# STM32L4R7 register map
File version: 2.0
CPU: CM4 r0p1, little endian, MPU, FPU, 4 interrupt priority bits
Registers are 32-bit, read-write, reset 0x0 unless marked. A register's access mark holds for its fields unless they carry their own. Offsets are from the block's base; [hi:lo] are bit positions; {n}, {i} and the like mark numbered series; 'fields as' and 'values as' point back to an identical list; <NAME> marks a mode.

## TIM2 — General-purpose-timers
Base 0x40000000
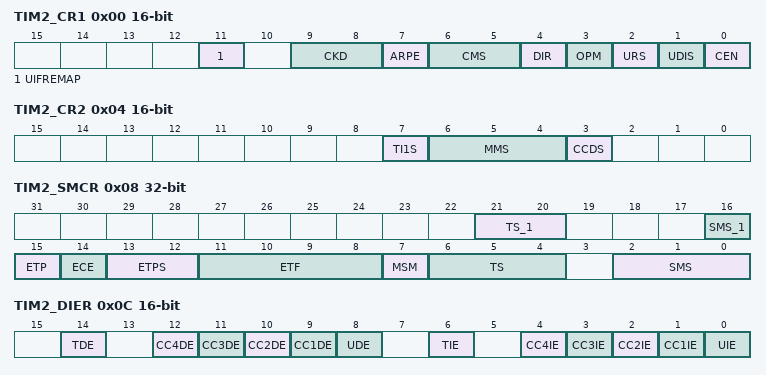
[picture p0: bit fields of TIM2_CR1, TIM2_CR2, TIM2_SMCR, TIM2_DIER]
0x00 TIM2_CR1 16-bit — TIM2 control register 1
  [11] UIFREMAP — UIF status bit remapping
    0=No remapping. UIF status bit is not copied to TIMx_CNT register bit 31.; 1=Remapping enabled. UIF status bit is copied to TIMx_CNT register bit 31.
  [9:8] CKD — Clock division This bit-field indicates the division ratio between the timer clock (CK_INT) frequency and sampling clock used by the digital filters (ETR, TIx),
    0=t<sub>DTS</sub> = t<sub>CK_INT</sub>; 1=t<sub>DTS</sub> = 2 t<sub>CK_INT</sub>; 2=t<sub>DTS</sub> = 4 t<sub>CK_INT</sub>
  [7] ARPE — Auto-reload preload enable
    0=TIMx_ARR register is not buffered; 1=TIMx_ARR register is buffered
  [6:5] CMS — Center-aligned mode selection Note: It is not allowed to switch from edge-aligned mode to center-aligned mode as long as the counter is enabled (CEN=1)
    0=Edge-aligned mode. The counter counts up or down depending on the direction bit (DIR).; 1=Center-aligned mode 1. The counter counts up and down alternatively. Output compare interrupt flags of channels configured in output (CCxS=00 in TIMx_CCMRx register) are set only when the counter is counting down.; 2=Center-aligned mode 2. The counter counts up and down alternatively. Output compare interrupt flags of channels configured in output (CCxS=00 in TIMx_CCMRx register) are set only when the counter is counting up.; 3=Center-aligned mode 3. The counter counts up and down alternatively. Output compare interrupt flags of channels configured in output (CCxS=00 in TIMx_CCMRx register) are set both when the counter is counting up or down.
  [4] DIR — Direction Note: This bit is read only when the timer is configured in Center-aligned mode or Encoder mode.
    0=Counter used as upcounter; 1=Counter used as downcounter
  [3] OPM — One-pulse mode
    0=Counter is not stopped at update event; 1=Counter stops counting at the next update event (clearing the bit CEN)
  [2] URS — Update request source This bit is set and cleared by software to select the UEV event sources. Counter overflow/underflow Setting the UG bit Update generation through the slave mode controller
    0=Any of the following events generate an update interrupt or DMA request if enabled. These events can be:; 1=Only counter overflow/underflow generates an update interrupt or DMA request if enabled
  [1] UDIS — Update disable This bit is set and cleared by software to enable/disable UEV event generation. Counter overflow/underflow Setting the UG bit Update generation through the slave mode controller Buffered registers are then loaded with their preload values.
    0=UEV enabled. The Update (UEV) event is generated by one of the following events:; 1=UEV disabled. The Update event is not generated, shadow registers keep their value (ARR, PSC, CCRx). However the counter and the prescaler are reinitialized if the UG bit is set or if a hardware reset is received from the slave mode controller.
  [0] CEN — Counter enable Note: External clock, gated mode and encoder mode can work only if the CEN bit has been previously set by software. However trigger mode can set the CEN bit automatically by hardware. CEN is cleared automatically in one-pulse mode, when an update event occurs.
    0=Counter disabled; 1=Counter enabled
0x04 TIM2_CR2 16-bit — TIM2 control register 2
  [7] TI1S — TI1 selection
    0=The TIMx_CH1 pin is connected to TI1 input; 1=The TIMx_CH1, CH2 and CH3 pins are connected to the TI1 input (XOR combination) See also Section 24.3.25: Interfacing with Hall sensors on page 713
  [6:4] MMS — Master mode selection These bits permit to select the information to be sent in master mode to slave timers for synchronization (TRGO). The combination is as follows: When the Counter Enable signal is controlled by the trigger input, there is a delay on TRGO, except if the master/slave mode is selected (see the MSM bit description in TIMx_SMCR register). Note: The clock of the slave timer or ADC must be enabled prior to receive events from the master timer, and must not be changed on-the-fly while triggers are received from the master timer.
    0=Reset - the UG bit from the TIMx_EGR register is used as trigger output (TRGO). If the reset is generated by the trigger input (slave mode controller configured in reset mode) then the signal on TRGO is delayed compared to the actual reset.; 1=Enable - the Counter enable signal, CNT_EN, is used as trigger output (TRGO). It is useful to start several timers at the same time or to control a window in which a slave timer is enabled. The Counter Enable signal is generated by a logic AND between CEN control bit and the trigger input when configured in gated mode.; 2=Update - The update event is selected as trigger output (TRGO). For instance a master timer can then be used as a prescaler for a slave timer.; 3=Compare Pulse - The trigger output send a positive pulse when the CC1IF flag is to be set (even if it was already high), as soon as a capture or a compare match occurred. (TRGO); {v}=Compare - OC{v-3}REFC signal is used as trigger output (TRGO) (v=4..7)
  [3] CCDS — Capture/compare DMA selection
    0=CCx DMA request sent when CCx event occurs; 1=CCx DMA requests sent when update event occurs
0x08 TIM2_SMCR — TIM2 slave mode control register
  [21:20] TS_1 — TS[4:3]
  [16] SMS_1 — SMS[3]
  [15] ETP — External trigger polarity This bit selects whether ETR or ETR is used for trigger operations
    0=ETR is non-inverted, active at high level or rising edge; 1=ETR is inverted, active at low level or falling edge
  [14] ECE — External clock enable This bit enables External clock mode 2. Note: Setting the ECE bit has the same effect as selecting external clock mode 1 with TRGI connected to ETRF (SMS=111 and TS=00111). Note: It is possible to simultaneously use external clock mode 2 with the following slave modes: reset mode, gated mode and trigger mode. Nevertheless, TRGI must not be connected to ETRF in this case (TS bits must not be 00111). Note: If external clock mode 1 and external clock mode 2 are enabled at the same time, the external clock input is ETRF.
    0=External clock mode 2 disabled; 1=External clock mode 2 enabled. The counter is clocked by any active edge on the ETRF signal.
  [13:12] ETPS — External trigger prescaler External trigger signal ETRP frequency must be at most 1/4 of CK_INT frequency. A prescaler can be enabled to reduce ETRP frequency. It is useful when inputting fast external clocks.
    0=Prescaler OFF; 1=ETRP frequency divided by 2; 2=ETRP frequency divided by 4; 3=ETRP frequency divided by 8
  [11:8] ETF — External trigger filter This bit-field then defines the frequency used to sample ETRP signal and the length of the digital filter applied to ETRP. The digital filter is made of an event counter in which N consecutive events are needed to validate a transition on the output:
    0=No filter, sampling is done at f<sub>DTS</sub>; 1=f<sub>SAMPLING</sub>=f<sub>CK_INT</sub>, N=2; 2=f<sub>SAMPLING</sub>=f<sub>CK_INT</sub>, N=4; 3=f<sub>SAMPLING</sub>=f<sub>CK_INT</sub>, N=8; 4=f<sub>SAMPLING</sub>=f<sub>DTS</sub>/2, N=6; 5=f<sub>SAMPLING</sub>=f<sub>DTS</sub>/2, N=8; 6=f<sub>SAMPLING</sub>=f<sub>DTS</sub>/4, N=6; 7=f<sub>SAMPLING</sub>=f<sub>DTS</sub>/4, N=8; 8=f<sub>SAMPLING</sub>=f<sub>DTS</sub>/8, N=6; 9=f<sub>SAMPLING</sub>=f<sub>DTS</sub>/8, N=8; 10=f<sub>SAMPLING</sub>=f<sub>DTS</sub>/16, N=5; 11=f<sub>SAMPLING</sub>=f<sub>DTS</sub>/16, N=6; 12=f<sub>SAMPLING</sub>=f<sub>DTS</sub>/16, N=8; 13=f<sub>SAMPLING</sub>=f<sub>DTS</sub>/32, N=5; 14=f<sub>SAMPLING</sub>=f<sub>DTS</sub>/32, N=6; 15=f<sub>SAMPLING</sub>=f<sub>DTS</sub>/32, N=8
  [7] MSM — Master/Slave mode
    0=No action; 1=The effect of an event on the trigger input (TRGI) is delayed to allow a perfect synchronization between the current timer and its slaves (through TRGO). It is useful if we want to synchronize several timers on a single external event.
  [6:4] TS — TS[0]: Trigger selection This bit-field selects the trigger input to be used to synchronize the counter. Others: Reserved See Table 179: TIMx internal trigger connection on page 846 for more details on ITRx meaning for each Timer. Note: These bits must be changed only when they are not used (e.g. when SMS=000) to avoid wrong edge detections at the transition.
    {v}=Internal Trigger {v} (ITR{v}) (v=0..3); 4=TI1 Edge Detector (TI1F_ED); 5=Filtered Timer Input 1 (TI1FP1); 6=Filtered Timer Input 2 (TI2FP2); 7=External Trigger input (ETRF)
  [2:0] SMS — SMS[0]: Slave mode selection When external signals are selected the active edge of the trigger signal (TRGI) is linked to the polarity selected on the external input (see Input Control register and Control Register description. reinitializes the counter, generates an update of the registers and starts the counter. Note: The gated mode must not be used if TI1F_ED is selected as the trigger input (TS=00100). Indeed, TI1F_ED outputs 1 pulse for each transition on TI1F, whereas the gated mode checks the level of the trigger signal. Note: The clock of the slave peripherals (timer, ADC, ...) receiving the TRGO or the TRGO2 signals must be enabled prior to receive events from the master timer, and the clock frequency (prescaler) must not be changed on-the-fly while triggers are received from the master timer.
    0=Slave mode disabled - if CEN = 1 then the prescaler is clocked directly by the internal clock; 1=Encoder mode 1 - Counter counts up/down on TI1FP1 edge depending on TI2FP2 level; 2=Encoder mode 2 - Counter counts up/down on TI2FP2 edge depending on TI1FP1 level; 3=Encoder mode 3 - Counter counts up/down on both TI1FP1 and TI2FP2 edges depending on the level of the other input; 4=Reset Mode - Rising edge of the selected trigger input (TRGI) reinitializes the counter and generates an update of the registers; 5=Gated Mode - The counter clock is enabled when the trigger input (TRGI) is high. The counter stops (but is not reset) as soon as the trigger becomes low. Both start and stop of the counter are controlled.; 6=Trigger Mode - The counter starts at a rising edge of the trigger TRGI (but it is not reset). Only the start of the counter is controlled.; 7=External Clock Mode 1 - Rising edges of the selected trigger (TRGI) clock the counter
0x0C TIM2_DIER 16-bit — TIM2 DMA/Interrupt enable register
  [14] TDE — Trigger DMA request enable
    0=Trigger DMA request disabled; 1=Trigger DMA request enabled
  [n+8] CC{n}DE (n=1..4) — Capture/Compare {n} DMA request enable
    0=CC{n} DMA request disabled; 1=CC{n} DMA request enabled
  [8] UDE — Update DMA request enable
    0=Update DMA request disabled; 1=Update DMA request enabled
  [6] TIE — Trigger interrupt enable
    0=Trigger interrupt disabled; 1=Trigger interrupt enabled
  [n] CC{n}IE (n=1..4) — Capture/Compare {n} interrupt enable
    0=CC{n} interrupt disabled; 1=CC{n} interrupt enabled
  [0] UIE — Update interrupt enable
    0=Update interrupt disabled; 1=Update interrupt enabled
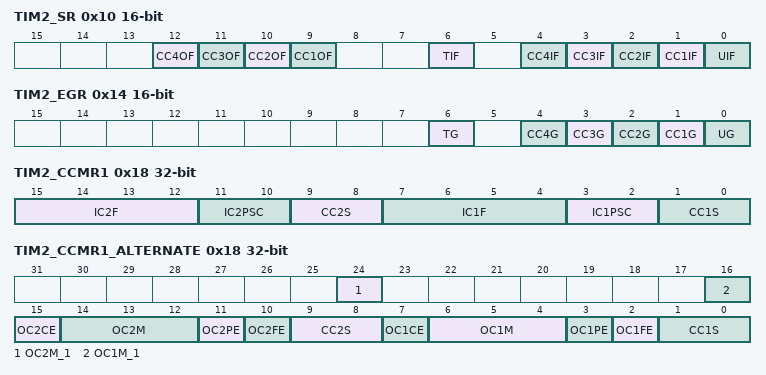
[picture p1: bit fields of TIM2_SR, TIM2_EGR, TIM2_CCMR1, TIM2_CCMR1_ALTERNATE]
0x10 TIM2_SR 16-bit — TIM2 status register
  [12] CC4OF — Capture/Compare 4 overcapture flag refer to CC1OF description
  [11] CC3OF — Capture/Compare 3 overcapture flag refer to CC1OF description
  [10] CC2OF — Capture/compare 2 overcapture flag refer to CC1OF description
  [9] CC1OF — Capture/Compare 1 overcapture flag This flag is set by hardware only when the corresponding channel is configured in input capture mode. It is cleared by software by writing it to 0 .
    0=No overcapture has been detected; 1=The counter value has been captured in TIMx_CCR1 register while CC1IF flag was already set
  [6] TIF — Trigger interrupt flag This flag is set by hardware on the TRG trigger event (active edge detected on TRGI input when the slave mode controller is enabled in all modes but gated mode. It is set when the counter starts or stops when gated mode is selected. It is cleared by software.
    0=No trigger event occurred; 1=Trigger interrupt pending
  [4] CC4IF — Capture/Compare 4 interrupt flag Refer to CC1IF description
  [3] CC3IF — Capture/Compare 3 interrupt flag Refer to CC1IF description
  [2] CC2IF — Capture/Compare 2 interrupt flag Refer to CC1IF description
  [1] CC1IF — Capture/compare 1 interrupt flag This flag is set by hardware. It is cleared by software (input capture or output compare mode) or by reading the TIMx_CCR1 register (input capture mode only). If channel CC1 is configured as output: this flag is set when the content of the counter TIMx_CNT matches the content of the TIMx_CCR1 register. When the content of TIMx_CCR1 is greater than the content of TIMx_ARR, the CC1IF bit goes high on the counter overflow (in up-counting and up/down-counting modes) or underflow (in down-counting mode). There are 3 possible options for flag setting in center-aligned mode, refer to the CMS bits in the TIMx_CR1 register for the full description. If channel CC1 is configured as input: this bit is set when counter value has been captured in TIMx_CCR1 register (an edge has been detected on IC1, as per the edge sensitivity defined with the CC1P and CC1NP bits setting, in TIMx_CCER).
    0=No compare match / No input capture occurred; 1=A compare match or an input capture occurred
  [0] UIF — Update interrupt flag This bit is set by hardware on an update event. It is cleared by software. At overflow or underflow (for TIM2 to TIM4) and if UDIS=0 in the TIMx_CR1 register. When CNT is reinitialized by software using the UG bit in TIMx_EGR register, if URS=0 and UDIS=0 in the TIMx_CR1 register. When CNT is reinitialized by a trigger event (refer to the synchro control register description), if URS=0 and UDIS=0 in the TIMx_CR1 register.
    0=No update occurred; 1=Update interrupt pending. This bit is set by hardware when the registers are updated:
0x14 TIM2_EGR 16-bit wo — TIM2 event generation register
  [6] TG — Trigger generation This bit is set by software in order to generate an event, it is automatically cleared by hardware.
    0=No action; 1=The TIF flag is set in TIMx_SR register. Related interrupt or DMA transfer can occur if enabled.
  [4] CC4G — Capture/compare 4 generation Refer to CC1G description
  [3] CC3G — Capture/compare 3 generation Refer to CC1G description
  [2] CC2G — Capture/compare 2 generation Refer to CC1G description
  [1] CC1G — Capture/compare 1 generation This bit is set by software in order to generate an event, it is automatically cleared by hardware. If channel CC1 is configured as output: CC1IF flag is set, Corresponding interrupt or DMA request is sent if enabled. If channel CC1 is configured as input: The current value of the counter is captured in TIMx_CCR1 register. The CC1IF flag is set, the corresponding interrupt or DMA request is sent if enabled. The CC1OF flag is set if the CC1IF flag was already high.
    0=No action; 1=A capture/compare event is generated on channel 1:
  [0] UG — Update generation This bit can be set by software, it is automatically cleared by hardware.
    0=No action; 1=Re-initialize the counter and generates an update of the registers. Note that the prescaler counter is cleared too (anyway the prescaler ratio is not affected). The counter is cleared if the center-aligned mode is selected or if DIR=0 (upcounting), else it takes the auto-reload value (TIMx_ARR) if DIR=1 (downcounting).
0x18 TIM2_CCMR1 — TIM2 capture/compare mode register 1
  [15:12] IC2F — Input capture 2 filter
  [11:10] IC2PSC — Input capture 2 prescaler
  [9:8] CC2S — Capture/compare 2 selection This bit-field defines the direction of the channel (input/output) as well as the used input. Note: CC2S bits are writable only when the channel is OFF (CC2E = 0 in TIMx_CCER).
    0=CC2 channel is configured as output; 1=CC2 channel is configured as input, IC2 is mapped on TI2; 2=CC2 channel is configured as input, IC2 is mapped on TI1; 3=CC2 channel is configured as input, IC2 is mapped on TRC. This mode is working only if an internal trigger input is selected through TS bit (TIMx_SMCR register)
  [7:4] IC1F — Input capture 1 filter This bit-field defines the frequency used to sample TI1 input and the length of the digital filter applied to TI1. The digital filter is made of an event counter in which N consecutive events are needed to validate a transition on the output:
    0=No filter, sampling is done at f <sub>DTS</sub>; 1=f<sub>SAMPLING</sub>=f<sub>CK_INT</sub>, N=2; 2=f<sub>SAMPLING</sub>=f<sub>CK_INT</sub>, N=4; 3=f<sub>SAMPLING</sub>=f<sub>CK_INT</sub>, N=8; 4=f<sub>SAMPLING</sub>=f<sub>DTS</sub>/2, N=6; 5=f<sub>SAMPLING</sub>=f<sub>DTS</sub>/2, N=8; 6=f<sub>SAMPLING</sub>=f<sub>DTS</sub>/4, N=6; 7=f<sub>SAMPLING</sub>=f<sub>DTS</sub>/4, N=8; 8=f<sub>SAMPLING</sub>=f<sub>DTS</sub>/8, N=6; 9=f<sub>SAMPLING</sub>=f<sub>DTS</sub>/8, N=8; 10=f<sub>SAMPLING</sub>=f<sub>DTS</sub>/16, N=5; 11=f<sub>SAMPLING</sub>=f<sub>DTS</sub>/16, N=6; 12=f<sub>SAMPLING</sub>=f<sub>DTS</sub>/16, N=8; 13=f<sub>SAMPLING</sub>=f<sub>DTS</sub>/32, N=5; 14=f<sub>SAMPLING</sub>=f<sub>DTS</sub>/32, N=6; 15=f<sub>SAMPLING</sub>=f<sub>DTS</sub>/32, N=8
  [3:2] IC1PSC — Input capture 1 prescaler This bit-field defines the ratio of the prescaler acting on CC1 input (IC1). The prescaler is reset as soon as CC1E=0 (TIMx_CCER register).
    0=no prescaler, capture is done each time an edge is detected on the capture input; 1=capture is done once every 2 events; 2=capture is done once every 4 events; 3=capture is done once every 8 events
  [1:0] CC1S — Capture/Compare 1 selection This bit-field defines the direction of the channel (input/output) as well as the used input. Note: CC1S bits are writable only when the channel is OFF (CC1E = 0 in TIMx_CCER).
    0=CC1 channel is configured as output; 1=CC1 channel is configured as input, IC1 is mapped on TI1; 2=CC1 channel is configured as input, IC1 is mapped on TI2; 3=CC1 channel is configured as input, IC1 is mapped on TRC. This mode is working only if an internal trigger input is selected through TS bit (TIMx_SMCR register)
0x18 TIM2_CCMR1_ALTERNATE (alternate view of TIM2_CCMR1) — TIM2 capture/compare mode register 1
  [24] OC2M_1 — OC2M[3]
  [16] OC1M_1 — OC1M[3]
  [15] OC2CE — Output compare 2 clear enable
  [14:12] OC2M — OC2M[2:0]: Output compare 2 mode refer to OC1M description on bits 6:4
  [11] OC2PE — Output compare 2 preload enable
  [10] OC2FE — Output compare 2 fast enable
  [9:8] CC2S — Capture/Compare 2 selection This bit-field defines the direction of the channel (input/output) as well as the used input. Note: CC2S bits are writable only when the channel is OFF (CC2E = 0 in TIMx_CCER).
    0=CC2 channel is configured as output; 1=CC2 channel is configured as input, IC2 is mapped on TI2; 2=CC2 channel is configured as input, IC2 is mapped on TI1; 3=CC2 channel is configured as input, IC2 is mapped on TRC. This mode is working only if an internal trigger input is selected through the TS bit (TIMx_SMCR register)
  [7] OC1CE — Output compare 1 clear enable
    0=OC1Ref is not affected by the ETRF input; 1=OC1Ref is cleared as soon as a High level is detected on ETRF input
  [6:4] OC1M — OC1M[2:0]: Output compare 1 mode These bits define the behavior of the output reference signal OC1REF from which OC1 and OC1N are derived. OC1REF is active high whereas OC1 and OC1N active level depends on CC1P and CC1NP bits. Note: In PWM mode, the OCREF level changes only when the result of the comparison changes or when the output compare mode switches from frozen mode to PWM mode. Note: The OC1M[3] bit is not contiguous, located in bit 16.
    0=Frozen - The comparison between the output compare register TIMx_CCR1 and the counter TIMx_CNT has no effect on the outputs. This mode can be used when the timer serves as a software timebase. When the frozen mode is enabled during timer operation, the output keeps the state (active or inactive) it had before entering the frozen state.; 1=Set channel 1 to active level on match. OC1REF signal is forced high when the counter TIMx_CNT matches the capture/compare register 1 (TIMx_CCR1).; 2=Set channel 1 to inactive level on match. OC1REF signal is forced low when the counter TIMx_CNT matches the capture/compare register 1 (TIMx_CCR1).; 3=Toggle - OC1REF toggles when TIMx_CNT=TIMx_CCR1; 4=Force inactive level - OC1REF is forced low; 5=Force active level - OC1REF is forced high; 6=PWM mode 1 - In upcounting, channel 1 is active as long as TIMx_CNT<TIMx_CCR1 else inactive. In downcounting, channel 1 is inactive (OC1REF= 0) as long as TIMx_CNT>TIMx_CCR1 else active (OC1REF=1).; 7=PWM mode 2 - In upcounting, channel 1 is inactive as long as TIMx_CNT<TIMx_CCR1 else active. In downcounting, channel 1 is active as long as TIMx_CNT>TIMx_CCR1 else inactive.
  [3] OC1PE — Output compare 1 preload enable
    0=Preload register on TIMx_CCR1 disabled. TIMx_CCR1 can be written at anytime, the new value is taken in account immediately.; 1=Preload register on TIMx_CCR1 enabled. Read/Write operations access the preload register. TIMx_CCR1 preload value is loaded in the active register at each update event.
  [2] OC1FE — Output compare 1 fast enable This bit decreases the latency between a trigger event and a transition on the timer output. It must be used in one-pulse mode (OPM bit set in TIMx_CR1 register), to have the output pulse starting as soon as possible after the starting trigger.
    0=CC1 behaves normally depending on counter and CCR1 values even when the trigger is ON. The minimum delay to activate CC1 output when an edge occurs on the trigger input is 5 clock cycles.; 1=An active edge on the trigger input acts like a compare match on CC1 output. Then, OC is set to the compare level independently from the result of the comparison. Delay to sample the trigger input and to activate CC1 output is reduced to 3 clock cycles. OCFE acts only if the channel is configured in PWM1 or PWM2 mode.
  [1:0] CC1S — Capture/Compare 1 selection This bit-field defines the direction of the channel (input/output) as well as the used input. Note: CC1S bits are writable only when the channel is OFF (CC1E = 0 in TIMx_CCER).
    values as TIM2_CCMR1.CC1S
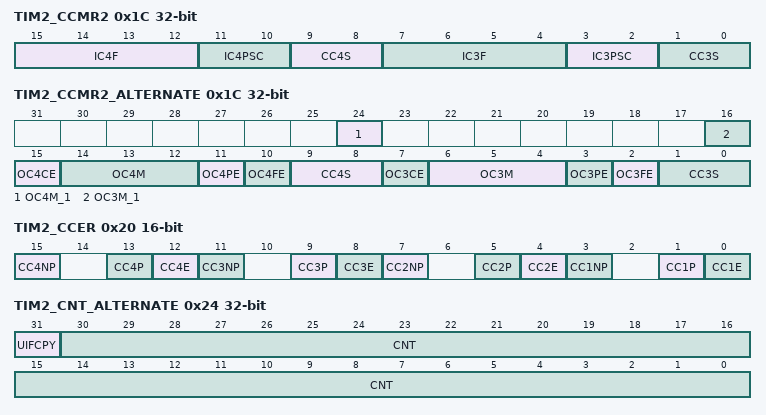
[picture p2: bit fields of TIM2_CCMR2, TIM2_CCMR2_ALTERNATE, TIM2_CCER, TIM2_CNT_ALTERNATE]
0x1C TIM2_CCMR2 — TIM2 capture/compare mode register 2
  [15:12] IC4F — Input capture 4 filter
  [11:10] IC4PSC — Input capture 4 prescaler
  [9:8] CC4S — Capture/Compare 4 selection This bit-field defines the direction of the channel (input/output) as well as the used input. Note: CC4S bits are writable only when the channel is OFF (CC4E = 0 in TIMx_CCER).
    0=CC4 channel is configured as output; 1=CC4 channel is configured as input, IC4 is mapped on TI4; 2=CC4 channel is configured as input, IC4 is mapped on TI3; 3=CC4 channel is configured as input, IC4 is mapped on TRC. This mode is working only if an internal trigger input is selected through TS bit (TIMx_SMCR register)
  [7:4] IC3F — Input capture 3 filter
  [3:2] IC3PSC — Input capture 3 prescaler
  [1:0] CC3S — Capture/Compare 3 selection This bit-field defines the direction of the channel (input/output) as well as the used input. Note: CC3S bits are writable only when the channel is OFF (CC3E = 0 in TIMx_CCER).
    0=CC3 channel is configured as output; 1=CC3 channel is configured as input, IC3 is mapped on TI3; 2=CC3 channel is configured as input, IC3 is mapped on TI4; 3=CC3 channel is configured as input, IC3 is mapped on TRC. This mode is working only if an internal trigger input is selected through TS bit (TIMx_SMCR register)
0x1C TIM2_CCMR2_ALTERNATE (alternate view of TIM2_CCMR2) — TIM2 capture/compare mode register 2
  [24] OC4M_1 — OC4M[3]
  [16] OC3M_1 — OC3M[3]
  [15] OC4CE — Output compare 4 clear enable
  [14:12] OC4M — OC4M[2:0]: Output compare 4 mode Refer to OC1M description (bits 6:4 in TIMx_CCMR1 register)
  [11] OC4PE — Output compare 4 preload enable
  [10] OC4FE — Output compare 4 fast enable
  [9:8] CC4S — Capture/Compare 4 selection This bit-field defines the direction of the channel (input/output) as well as the used input. Note: CC4S bits are writable only when the channel is OFF (CC4E = 0 in TIMx_CCER).
    values as TIM2_CCMR2.CC4S
  [7] OC3CE — Output compare 3 clear enable
  [6:4] OC3M — OC3M[2:0]: Output compare 3 mode Refer to OC1M description (bits 6:4 in TIMx_CCMR1 register)
  [3] OC3PE — Output compare 3 preload enable
  [2] OC3FE — Output compare 3 fast enable
  [1:0] CC3S — Capture/Compare 3 selection This bit-field defines the direction of the channel (input/output) as well as the used input. Note: CC3S bits are writable only when the channel is OFF (CC3E = 0 in TIMx_CCER).
    values as TIM2_CCMR2.CC3S
0x20 TIM2_CCER 16-bit — TIM2 capture/compare enable register
  [15] CC4NP — Capture/Compare 4 output Polarity. Refer to CC1NP description
  [13] CC4P — Capture/Compare 4 output Polarity. Refer to CC1P description
  [12] CC4E — Capture/Compare 4 output enable. refer to CC1E description
  [11] CC3NP — Capture/Compare 3 output Polarity. Refer to CC1NP description
  [9] CC3P — Capture/Compare 3 output Polarity. Refer to CC1P description
  [8] CC3E — Capture/Compare 3 output enable. Refer to CC1E description
  [7] CC2NP — Capture/Compare 2 output Polarity. Refer to CC1NP description
  [5] CC2P — Capture/Compare 2 output Polarity. refer to CC1P description
  [4] CC2E — Capture/Compare 2 output enable. Refer to CC1E description
  [3] CC1NP — Capture/Compare 1 output Polarity. CC1 channel configured as output: CC1NP must be kept cleared in this case. CC1 channel configured as input: This bit is used in conjunction with CC1P to define TI1FP1/TI2FP1 polarity. refer to CC1P description.
  [1] CC1P — Capture/Compare 1 output Polarity. When CC1 channel is configured as input, both CC1NP/CC1P bits select the active polarity of TI1FP1 and TI2FP1 for trigger or capture operations. CC1NP=0, CC1P=0: non-inverted/rising edge. The circuit is sensitive to TIxFP1 rising edge (capture or trigger operations in reset, external clock or trigger mode), TIxFP1 is not inverted (trigger operation in gated mode or encoder mode). CC1NP=0, CC1P=1: inverted/falling edge. The circuit is sensitive to TIxFP1 falling edge (capture or trigger operations in reset, external clock or trigger mode), TIxFP1 is inverted (trigger operation in gated mode or encoder mode). CC1NP=1, CC1P=1: non-inverted/both edges. The circuit is sensitive to both TIxFP1 rising and falling edges (capture or trigger operations in reset, external clock or trigger mode), TIxFP1is not inverted (trigger operation in gated mode). This configuration must not be used in encoder mode. CC1NP=1, CC1P=0: This configuration is reserved, it must not be used.
    0=OC1 active high (output mode) / Edge sensitivity selection (input mode, see below); 1=OC1 active low (output mode) / Edge sensitivity selection (input mode, see below)
  [0] CC1E — Capture/Compare 1 output enable.
    0=Capture mode disabled / OC1 is not active; 1=Capture mode enabled / OC1 signal is output on the corresponding output pin
0x24 TIM2_CNT — TIM2 counter
  [31:0] CNT — Least significant part of counter value
0x24 TIM2_CNT_ALTERNATE (alternate view of TIM2_CNT) — TIM2 counter
  [31] UIFCPY — UIF Copy This bit is a read-only copy of the UIF bit of the TIMx_ISR register
  [30:0] CNT — Least significant part of counter value
0x28 TIM2_PSC 16-bit — TIM2 prescaler
  [15:0] PSC — Prescaler value The counter clock frequency CK_CNT is equal to f<sub>CK_PSC</sub> / (PSC[15:0] + 1). PSC contains the value to be loaded in the active prescaler register at each update event (including when the counter is cleared through UG bit of TIMx_EGR register or through trigger controller when configured in reset mode ).
0x2C TIM2_ARR reset 0xFFFFFFFF — TIM2 auto-reload register
  [31:0] ARR — Low Auto-reload value ARR is the value to be loaded in the actual auto-reload register. Refer to the Section 25.3.1: Time-base unit on page 786 for more details about ARR update and behavior. The counter is blocked while the auto-reload value is null.
0x34 TIM2_CCR1 — TIM2 capture/compare register 1
  [31:0] CCR1 — Low Capture/Compare 1 value If channel CC1 is configured as output: CCR1 is the value to be loaded in the actual capture/compare 1 register (preload value). It is loaded permanently if the preload feature is not selected in the TIMx_CCMR1 register (bit OC1PE). Else the preload value is copied in the active capture/compare 1 register when an update event occurs. The active capture/compare register contains the value to be compared to the counter TIMx_CNT and signaled on OC1 output. If channel CC1is configured as input: CCR1 is the counter value transferred by the last input capture 1 event (IC1). The TIMx_CCR1 register is read-only and cannot be programmed.
0x38 TIM2_CCR2 — TIM2 capture/compare register 2
  [31:0] CCR2 — Low Capture/Compare 2 value If channel CC2 is configured as output: CCR2 is the value to be loaded in the actual capture/compare 2 register (preload value). It is loaded permanently if the preload feature is not selected in the TIMx_CCMR1 register (bit OC2PE). Else the preload value is copied in the active capture/compare 2 register when an update event occurs. The active capture/compare register contains the value to be compared to the counter TIMx_CNT and signalled on OC2 output. If channel CC2 is configured as input: CCR2 is the counter value transferred by the last input capture 2 event (IC2). The TIMx_CCR2 register is read-only and cannot be programmed.
0x3C TIM2_CCR3 — TIM2 capture/compare register 3
  [31:0] CCR3 — Low Capture/Compare value If channel CC3 is configured as output: CCR3 is the value to be loaded in the actual capture/compare 3 register (preload value). It is loaded permanently if the preload feature is not selected in the TIMx_CCMR2 register (bit OC3PE). Else the preload value is copied in the active capture/compare 3 register when an update event occurs. The active capture/compare register contains the value to be compared to the counter TIMx_CNT and signalled on OC3 output. If channel CC3is configured as input: CCR3 is the counter value transferred by the last input capture 3 event (IC3). The TIMx_CCR3 register is read-only and cannot be programmed.
0x40 TIM2_CCR4 — TIM2 capture/compare register 4
  [31:0] CCR4 — Low Capture/Compare value if CC4 channel is configured as output (CC4S bits): CCR4 is the value to be loaded in the actual capture/compare 4 register (preload value). It is loaded permanently if the preload feature is not selected in the TIMx_CCMR2 register (bit OC4PE). Else the preload value is copied in the active capture/compare 4 register when an update event occurs. The active capture/compare register contains the value to be compared to the counter TIMx_CNT and signalled on OC4 output. if CC4 channel is configured as input (CC4S bits in TIMx_CCMR4 register): CCR4 is the counter value transferred by the last input capture 4 event (IC4). The TIMx_CCR4 register is read-only and cannot be programmed.
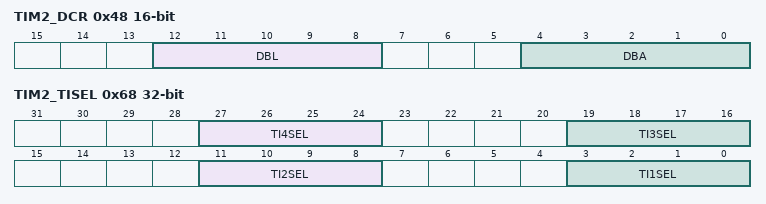
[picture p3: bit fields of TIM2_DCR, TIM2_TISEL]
0x48 TIM2_DCR 16-bit — TIM2 DMA control register
  [12:8] DBL — DMA burst length This 5-bit vector defines the number of DMA transfers (the timer recognizes a burst transfer when a read or a write access is done to the TIMx_DMAR address). ...
    0=1 transfer,; 1=2 transfers,; 2=3 transfers,; 17=18 transfers
  [4:0] DBA — DMA base address This 5-bit vector defines the base-address for DMA transfers (when read/write access are done through the TIMx_DMAR address). DBA is defined as an offset starting from the address of the TIMx_CR1 register. Example: ... Example: Let us consider the following transfer: DBL = 7 transfers & DBA = TIMx_CR1. In this case the transfer is done to/from 7 registers starting from the TIMx_CR1 address.
    0=TIMx_CR1; 1=TIMx_CR2; 2=TIMx_SMCR
0x4C TIM2_DMAR 16-bit — TIM2 DMA address for full transfer
  [15:0] DMAB — DMA register for burst accesses A read or write operation to the DMAR register accesses the register located at the address (TIMx_CR1 address) + (DBA + DMA index) x 4 where TIMx_CR1 address is the address of the control register 1, DBA is the DMA base address configured in TIMx_DCR register, DMA index is automatically controlled by the DMA transfer, and ranges from 0 to DBL (DBL configured in TIMx_DCR).
0x60 TIM2_AF1 — TIM2 alternate function option register 1
  [17:14] ETRSEL — ETR source selection These bits select the ETR input source. Others: Reserved
    0=ETR input is connected to I/O; 1=COMP1 output; 2=COMP2 output; 3=LSE; 4=SAI1 FS_A; 5=SAI1 FS_B
0x68 TIM2_TISEL — TIM2 timer input selection register
  [27:24] TI4SEL — TI4[0] to TI4[15] input selection These bits select the TI4[0] to TI4[15] input source. Others: Reserved
    0=TIM2_CH4 input; 1=COMP1 output; 2=COMP2 output; 3=COMP1 output OR COMP2 output
  [19:16] TI3SEL — TI3[0] to TI3[15] input selection These bits select the TI3[0] to TI3[15] input source. Others: Reserved
    0=TIM2_CH3 input
  [11:8] TI2SEL — TI2[0] to TI2[15] input selection These bits select the TI2[0] to TI2[15] input source. Others: Reserved
    0=TIM2_CH2 input
  [3:0] TI1SEL — TI1[0] to TI1[15] input selection These bits select the TI1[0] to TI1[15] input source. Others: Reserved
    0=TIM2_CH1 input

## TIM3 — General-purpose-timers
Base 0x40000400
Registers as TIM2 (with TIM2 read as TIM3); these are added or differ:
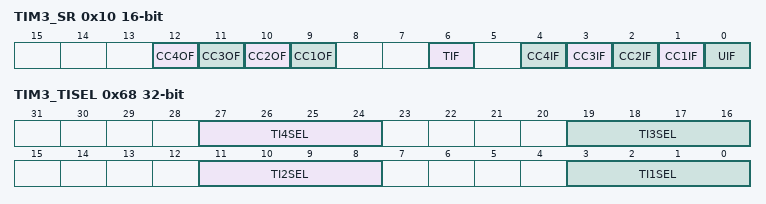
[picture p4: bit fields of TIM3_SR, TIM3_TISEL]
0x10 TIM3_SR 16-bit — TIM3 status register
  fields as TIM2.TIM2_SR
0x60 TIM3_AF1 — TIM3 alternate function option register 1
  [17:14] ETRSEL — ETR source selection These bits select the ETR input source. Others: Reserved
    0=ETR input is connected to I/O; 1=COMP1 output
0x68 TIM3_TISEL — TIM3 timer input selection register
  [27:24] TI4SEL — TI4[0] to TI4[15] input selection These bits select the TI4[0] to TI4[15] input source. Others: Reserved
    0=TIM3_CH4 input
  [19:16] TI3SEL — TI3[0] to TI3[15] input selection These bits select the TI3[0] to TI3[15] input source. Others: Reserved
    0=TIM3_CH3 input
  [11:8] TI2SEL — TI2[0] to TI2[15] input selection These bits select the TI2[0] to TI2[15] input source. Others: Reserved
    0=TIM3_CH2 input
  [3:0] TI1SEL — TI1[0] to TI1[15] input selection These bits select the TI1[0] to TI1[15] input source. Others: Reserved
    0=TIM3_CH1 input; 1=COMP1 output; 2=COMP2 output; 3=COMP1 output OR COMP2 output

## TIM4 — General-purpose-timers
Base 0x40000800
Registers as TIM2 (with TIM2 read as TIM4); these are added or differ:
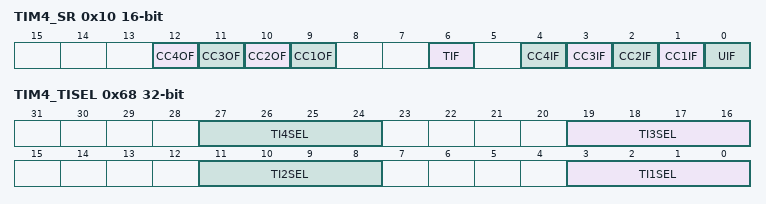
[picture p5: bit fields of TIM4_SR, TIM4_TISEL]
0x10 TIM4_SR 16-bit — TIM4 status register
  fields as TIM2.TIM2_SR
0x60 TIM4_AF1 — TIM4 alternate function option register 1
  [17:14] ETRSEL — ETR source selection These bits select the ETR input source. Others: Reserved
    0=ETR input is connected to I/O
0x68 TIM4_TISEL — TIM4 timer input selection register
  [8n-5:8n-8] TI{n}SEL (n=1..4) — TI{n}[0] to TI{n}[15] input selection These bits select the TI{n}[0] to TI{n}[15] input source. Others: Reserved
    0=TIM4_CH{n} input

## TIM5 — General-purpose-timers
Base 0x40000C00
Registers as TIM3 (with TIM3 read as TIM5); these are added or differ:
0x60 TIM5_AF1 — TIM5 alternate function option register 1
  [17:14] ETRSEL — ETR source selection These bits select the ETR input source. Others: Reserved
    0=ETR input is connected to I/O; 1=SAI2 FS_A connected to ETR input; 2=SAI2 FS_B connected to ETR input
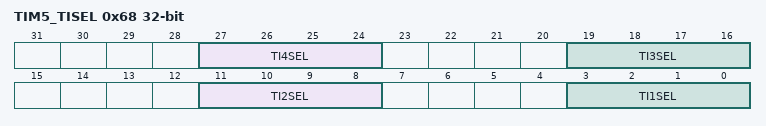
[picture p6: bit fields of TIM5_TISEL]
0x68 TIM5_TISEL — TIM5 timer input selection register
  [27:24] TI4SEL — TI4[0] to TI4[15] input selection These bits select the TI4[0] to TI4[15] input source. Others: Reserved
    0=TIM5_CH4 input
  [19:16] TI3SEL — TI3[0] to TI3[15] input selection These bits select the TI3[0] to TI3[15] input source. Others: Reserved
    0=TIM5_CH3 input
  [11:8] TI2SEL — TI2[0] to TI2[15] input selection These bits select the TI2[0] to TI2[15] input source. Others: Reserved
    0=TIM5_CH2 input
  [3:0] TI1SEL — TI1[0] to TI1[15] input selection These bits select the TI1[0] to TI1[15] input source. Others: Reserved
    0=TIM5_CH1 input; 1=fdcan1_tmp; 2=fdcan1_rtp

## Notices in the file
Copyright (c) 2023 STMicroelectronics.
SPDX-License-Identifier: Apache-2.0
Licensed under the Apache License, Version 2.0 (the "License");
you may not use this file except in compliance with the License.
You may obtain a copy of the License at
http://www.apache.org/licenses/LICENSE-2.0
Unless required by applicable law or agreed to in writing, software
distributed under the License is distributed on an "AS IS" BASIS,
WITHOUT WARRANTIES OR CONDITIONS OF ANY KIND, either express or implied.
See the License for the specific language governing permissions and
limitations under the License.
